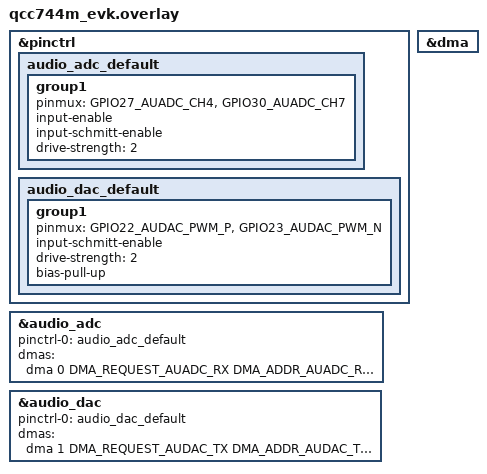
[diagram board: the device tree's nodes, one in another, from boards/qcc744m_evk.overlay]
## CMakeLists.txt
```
# Copyright (c) 2026 Qualcomm Technologies, Inc. and/or its subsidiaries
# SPDX-License-Identifier: BSD-3-Clause

cmake_minimum_required(VERSION 3.20.0)

find_package(Zephyr REQUIRED HINTS $ENV{ZEPHYR_BASE})
project(demo_audio_adc_dac_loopback)

target_sources(app PRIVATE src/main.c)
```

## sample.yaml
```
# Copyright (c) 2026 Qualcomm Technologies, Inc. and/or its subsidiaries
# SPDX-License-Identifier: BSD-3-Clause

sample:
  name: Audio ADC/DAC driver sample for Opal
common:
  timeout: 120
  harness: console
  harness_config:
    type: multi_line
    ordered: true
    regex:
      - "Start loopback"
      - "Stop loopback"
      - "Start loopback"
      - "Stop loopback"
tests:
  qcc7xx.sample.drivers.audio.adc_dac_loopback:
    tags: 
      - audio 
      - adc 
      - dac
    platform_allow:
      - qcc744m_evk
      - qcc748m_evk
```

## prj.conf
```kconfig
CONFIG_AUDIO=y
CONFIG_AUDIO_ADC=y
CONFIG_AUDIO_DAC=y
```

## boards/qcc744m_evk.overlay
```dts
/*
 * Copyright (c) 2026 Qualcomm Technologies, Inc. and/or its subsidiaries
 *
 * SPDX-License-Identifier: BSD-3-Clause
 */

&pinctrl {
	status = "okay";
	audio_adc_default: audio_adc_default {
		group1 {
			pinmux = <GPIO27_AUADC_CH4>,
				 <GPIO30_AUADC_CH7>;
			input-enable;
			input-schmitt-enable;
			drive-strength = <2>;
		};
	};
	audio_dac_default: audio_dac_default {
		group1 {
			pinmux = <GPIO22_AUDAC_PWM_P>,
				 <GPIO23_AUDAC_PWM_N>;
			input-schmitt-enable;
			drive-strength = <2>;
			bias-pull-up;
		};
	};
};

&dma {
	status = "okay";
};

&audio_adc {
	status = "okay";
	pinctrl-0 = <&audio_adc_default>;
	pinctrl-names = "default";
	dmas = <&dma 0 DMA_REQUEST_AUADC_RX DMA_ADDR_AUADC_RDR>;
};

&audio_dac {
	status = "okay";
	pinctrl-0 = <&audio_dac_default>;
	pinctrl-names = "default";
	dmas = <&dma 1 DMA_REQUEST_AUDAC_TX DMA_ADDR_AUDAC_TDR>;
};
```

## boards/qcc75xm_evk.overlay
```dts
/*
 * Copyright (c) 2026 Qualcomm Technologies, Inc. and/or its subsidiaries
 *
 * SPDX-License-Identifier: BSD-3-Clause
 */

&pinctrl {
	status = "okay";
	audio_adc_default: audio_adc_default {
		group1 {
			pinmux = <GPIO27_ADC1_CH3>,
				<GPIO29_ADC1_CH4>;
			input-enable;
			input-schmitt-enable;
			drive-strength = <2>;
		};
	};
	audio_dac_default: audio_dac_default {
		group1 {
			pinmux = <GPIO16_AUDAC_PWM_P>,
				<GPIO14_AUDAC_PWM_N>;
			input-schmitt-enable;
			drive-strength = <2>;
			bias-pull-up;
		};
	};
};

&dma {
	status = "okay";
};

&audio_adc {
	status = "okay";
	pinctrl-0 = <&audio_adc_default>;
	pinctrl-names = "default";
	dmas = <&dma 0 DMA_REQUEST_AUADC_RX DMA_ADDR_ADC_RDR>; /* AUADC ?*/
};

&audio_dac {
	status = "okay";
	pinctrl-0 = <&audio_dac_default>;
	pinctrl-names = "default";
	dmas = <&dma 1 DMA_REQUEST_AUDAC_TX DMA_ADDR_DAC_TDR>; /* AUDAC ?*/
};
```

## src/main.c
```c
/*
 * Copyright (c) 2026 Qualcomm Technologies, Inc. and/or its subsidiaries
 * SPDX-License-Identifier: Apache-2.0
 */

#include <zephyr/drivers/audio/audio_adc.h>
#include <zephyr/drivers/audio/audio_dac.h>

#define AUDIO_BUFFER_SIZE 16000

int main(void)
{
	const struct device *const audio_adc_dev = DEVICE_DT_GET(DT_NODELABEL(audio_adc));
	const struct device *const audio_dac_dev = DEVICE_DT_GET(DT_NODELABEL(audio_dac));
	static __aligned(32) uint8_t audio_buffer[AUDIO_BUFFER_SIZE];
	int err;

	if (!device_is_ready(audio_adc_dev)) {
		printf("Audio ADC controller device %s not ready\n", audio_adc_dev->name);
		return 0;
	}

	struct audio_adc_cfg adc_cfg = {
		.buffer = audio_buffer,
		.buffer_size = AUDIO_BUFFER_SIZE,
		.sampling_rate = AUDIO_PCM_RATE_32K,
		.sample_width = AUDIO_PCM_WIDTH_16_BITS,
		.differential = false,
		.coupling_mode = AC,
		.input_positive = 4,
		.gain_db = 9
	};
	err = audio_adc_configure(audio_adc_dev, &adc_cfg);
	if (err < 0) {
		printf("Error in audio_adc_configure: %d\n", err);
	}

	if (!device_is_ready(audio_dac_dev)) {
		printf("Audio DAC controller device %s not ready\n", audio_dac_dev->name);
		return 0;
	}

	struct audio_dac_cfg dac_cfg = {
		.buffer = audio_buffer,
		.buffer_size = AUDIO_BUFFER_SIZE,
		.sampling_rate = AUDIO_PCM_RATE_32K,
		.sample_width = AUDIO_PCM_WIDTH_16_BITS
	};
	err = audio_dac_configure(audio_dac_dev, &dac_cfg);
	if (err < 0) {
		printf("Error in audio_dac_configure: %d\n", err);
	}

	while (true) {
		printf("Start loopback\n");
		err = audio_adc_start(audio_adc_dev);
		if (err < 0) {
			printf("Error in audio_adc_start: %d\n", err);
		}
		// Sleep some time to get audio buffer filled.
		k_sleep(K_MSEC(200));
		err = audio_dac_start(audio_dac_dev);
		if (err < 0) {
			printf("Error in audio_dac_start: %d\n", err);
		}
		k_sleep(K_SECONDS(5));

		printf("Stop loopback\n");
		err = audio_dac_stop(audio_dac_dev);
		if (err < 0) {
			printf("Error in audio_dac_stop: %d\n", err);
		}
		err = audio_adc_stop(audio_adc_dev);
		if (err < 0) {
			printf("Error in audio_adc_stop: %d\n", err);
		}
		k_sleep(K_SECONDS(5));
	}

	return 0;
}
```
